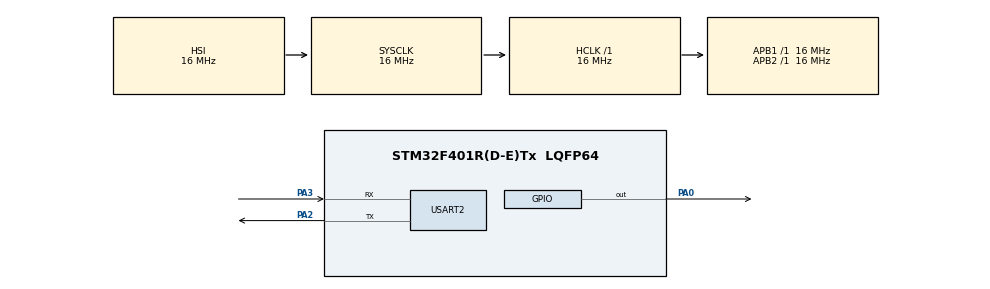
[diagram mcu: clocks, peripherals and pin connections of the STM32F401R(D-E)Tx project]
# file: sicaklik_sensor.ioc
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Mcu.Family=STM32F4
Mcu.Name=STM32F401R(D-E)Tx
Mcu.Package=LQFP64
NVIC.PriorityGroup=NVIC_PRIORITYGROUP_4
NVIC.USART2_IRQn=true\:0\:0\:false\:false\:true\:true\:true\:true
PA0-WKUP.GPIO_ModeDefaultOutputPP=GPIO_MODE_OUTPUT_OD
PA0-WKUP.GPIO_PuPd=GPIO_NOPULL
PA0-WKUP.PinState=GPIO_PIN_SET
PA0-WKUP.Signal=GPIO_Output
PA13.Mode=Serial_Wire
PA13.Signal=SYS_JTMS-SWDIO
PA14.Mode=Serial_Wire
PA14.Signal=SYS_JTCK-SWCLK
PA2.Mode=Asynchronous
PA2.Signal=USART2_TX
PA3.Mode=Asynchronous
PA3.Signal=USART2_RX
PH0\ -\ OSC_IN.Mode=HSE-External-Oscillator
PH0\ -\ OSC_IN.Signal=RCC_OSC_IN
PH1\ -\ OSC_OUT.Mode=HSE-External-Oscillator
PH1\ -\ OSC_OUT.Signal=RCC_OSC_OUT
ProjectManager.HeapSize=0x200
ProjectManager.StackSize=0x400
ProjectManager.TargetToolchain=STM32CubeIDE
RCC.AHBFreq_Value=16000000
RCC.APB1Freq_Value=16000000
RCC.APB2Freq_Value=16000000
RCC.CortexFreq_Value=16000000
RCC.HSE_VALUE=25000000
RCC.HSI_VALUE=16000000
RCC.LSE_VALUE=32768
RCC.SYSCLKFreq_VALUE=16000000
RCC.VCOOutputFreq_Value=192000000
TIM2.AutoReloadPreload=TIM_AUTORELOAD_PRELOAD_ENABLE
TIM2.Period=65535
TIM2.Prescaler=15
USART2.VirtualMode=VM_ASYNC
VP_TIM2_VS_ClockSourceINT.Mode=Internal
board=custom

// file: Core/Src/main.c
/* USER CODE BEGIN Header */
/**
  ******************************************************************************
  * @file           : main.c
  * @brief          : DS18B20 Telemetry System - 3 Sensors + Loop Hz + Uptime
  ******************************************************************************
  */
/* USER CODE END Header */
#include "main.h"
#include "stdio.h"

TIM_HandleTypeDef htim2;

UART_HandleTypeDef huart2;

/* USER CODE BEGIN PV */
// Sensör Kimlikleri (Sabit)
uint8_t S1_ID[8] = {0x28, 0x86, 0x84, 0x37, 0x00, 0x00, 0x00, 0x5C};
uint8_t S2_ID[8] = {0x28, 0xCC, 0x48, 0x38, 0x00, 0x00, 0x00, 0x7F};
uint8_t S3_ID[8] = {0x28, 0xE7, 0xB4, 0x36, 0x00, 0x00, 0x00, 0xA3};

// Sıcaklık ve Telemetri Değişkenleri
float T1 = 0, T2 = 0, T3 = 0;
float Loop_Hz = 0;
uint32_t last_tick = 0;
uint32_t current_uptime = 0;

char msg_buffer[150];
/* USER CODE END PV */

void SystemClock_Config(void);
static void MX_GPIO_Init(void);
static void MX_TIM2_Init(void);
static void MX_USART2_UART_Init(void);
/* USER CODE BEGIN PFP */
void delay_us (uint16_t us);
uint8_t DS18B20_Start (void);
void DS18B20_Write (uint8_t data);
uint8_t DS18B20_Read (void);
void DS18B20_Config9Bit(void);
float DS18B20_Read_By_ID(uint8_t *ID);
/* USER CODE END PFP */

/* USER CODE BEGIN 0 */
void delay_us (uint16_t us) {
    __HAL_TIM_SET_COUNTER(&htim2, 0);
    while (__HAL_TIM_GET_COUNTER(&htim2) < us);
}

void DS18B20_Config9Bit(void) {
    if (DS18B20_Start()) {
        DS18B20_Write(0xCC); // Skip ROM
        DS18B20_Write(0x4E); // Write Scratchpad
        DS18B20_Write(0x00); // TH
        DS18B20_Write(0x00); // TL
        DS18B20_Write(0x1F); // 9-bit resolution
    }
}

uint8_t DS18B20_Start (void) {
    uint8_t Response = 0;
    HAL_GPIO_WritePin(GPIOA, GPIO_PIN_0, 0);
    delay_us(480);
    HAL_GPIO_WritePin(GPIOA, GPIO_PIN_0, 1);
    delay_us(80);
    if (!(HAL_GPIO_ReadPin(GPIOA, GPIO_PIN_0))) Response = 1;
    else Response = 0;
    delay_us(400);
    return Response;
}

void DS18B20_Write (uint8_t data) {
    for (int i=0; i<8; i++) {
        if ((data & (1<<i)) != 0) {
            HAL_GPIO_WritePin(GPIOA, GPIO_PIN_0, 0);
            delay_us(1);
            HAL_GPIO_WritePin(GPIOA, GPIO_PIN_0, 1);
            delay_us(60);
        } else {
            HAL_GPIO_WritePin(GPIOA, GPIO_PIN_0, 0);
            delay_us(60);
            HAL_GPIO_WritePin(GPIOA, GPIO_PIN_0, 1);
        }
    }
}

uint8_t DS18B20_Read (void) {
    uint8_t value = 0;
    for (int i=0; i<8; i++) {
        HAL_GPIO_WritePin(GPIOA, GPIO_PIN_0, 0);
        delay_us(2);
        HAL_GPIO_WritePin(GPIOA, GPIO_PIN_0, 1);
        delay_us(10);
        if (HAL_GPIO_ReadPin(GPIOA, GPIO_PIN_0)) value |= (1<<i);
        delay_us(50);
    }
    return value;
}

float DS18B20_Read_By_ID(uint8_t *ID) {
    uint8_t b1, b2;
    if (DS18B20_Start()) {
        DS18B20_Write(0x55); // Match ROM
        for (int i=0; i<8; i++) DS18B20_Write(ID[i]);
        DS18B20_Write(0xBE); // Read Scratchpad
        b1 = DS18B20_Read();
        b2 = DS18B20_Read();
        return (float)((int16_t)(b2 << 8) | b1) / 16.0;
    }
    return -99.0;
}
/* USER CODE END 0 */

int main(void)
{

  /* MCU Configuration--------------------------------------------------------*/

  /* Reset of all peripherals, Initializes the Flash interface and the Systick. */
  HAL_Init();

  /* Configure the system clock */
  SystemClock_Config();

  /* Initialize all configured peripherals */
  MX_GPIO_Init();
  MX_TIM2_Init();
  MX_USART2_UART_Init();
  /* USER CODE BEGIN 2 */
  HAL_TIM_Base_Start(&htim2);
  DS18B20_Config9Bit(); // Sensörleri hızlandır

  HAL_UART_Transmit(&huart1, (uint8_t*)"Telemetri Basliyor...\r\n", 23, 100);
  last_tick = HAL_GetTick();
  /* USER CODE END 2 */

  /* Infinite loop */
  while (1)
  {
	  // --- 1. FREKANS (Hz) VE UPTIME HESAPLAMA ---
	        uint32_t current_time = HAL_GetTick();
	        uint32_t delta = current_time - last_tick;

	        if(delta > 0) {
	            Loop_Hz = 1000.0f / delta; // Döngü kaç Hz ile dönüyor?
	        }
	        last_tick = current_time;
	        current_uptime = current_time / 1000; // Saniye cinsinden çalışma süresi

	        // --- 2. SENSÖRLERE ÖLÇÜM EMRİ VER (SKIP ROM) ---
	        DS18B20_Start();
	        DS18B20_Write(0xCC); // Tüm sensörlere seslen
	        DS18B20_Write(0x44); // Sıcaklığı ölçmeye başlayın (Convert T)

	        // 9-bit modunda 100ms beklemek yeterlidir (Hızlı okuma için)
	        HAL_Delay(100);

	        // --- 3. VERİLERİ KİMLİKLERİNE (ID) GÖRE TEK TEK ÇEK ---
	        T1 = DS18B20_Read_By_ID(S1_ID);
	        T2 = DS18B20_Read_By_ID(S2_ID);
	        T3 = DS18B20_Read_By_ID(S3_ID);

	        // --- 4. RASPBERRY PI İÇİN PAKETLE VE GÖNDER (USART2!) ---
	        char msg[128];
	        // Format: S1:24.50|S2:25.10|S3:23.85|HZ:9.50|UP:123
	        int len = sprintf(msg, "S1:%.2f|S2:%.2f|S3:%.2f|HZ:%.2f|UP:%lu\n",
	                          T1, T2, T3, Loop_Hz, (unsigned long)current_uptime);

	        // USB üzerinden göndermek için huart2 kullanıyoruz
	        HAL_UART_Transmit(&huart2, (uint8_t*)msg, len, 100);

	        // --- 5. SİSTEMİ BİRAZ RAHATLAT (OPSİYONEL) ---
	        // Arayüzün saniyede 10 paket (10Hz) alması yeterlidir.
	        HAL_Delay(10);
  }
}

void SystemClock_Config(void)
{
  RCC_OscInitTypeDef RCC_OscInitStruct = {0};
  RCC_ClkInitTypeDef RCC_ClkInitStruct = {0};

  /** Configure the main internal regulator output voltage
  */
  __HAL_RCC_PWR_CLK_ENABLE();
  __HAL_PWR_VOLTAGESCALING_CONFIG(PWR_REGULATOR_VOLTAGE_SCALE2);

  /** Initializes the RCC Oscillators according to the specified parameters
  * in the RCC_OscInitTypeDef structure.
  */
  RCC_OscInitStruct.OscillatorType = RCC_OSCILLATORTYPE_HSI;
  RCC_OscInitStruct.HSIState = RCC_HSI_ON;
  RCC_OscInitStruct.HSICalibrationValue = RCC_HSICALIBRATION_DEFAULT;
  RCC_OscInitStruct.PLL.PLLState = RCC_PLL_NONE;
  if (HAL_RCC_OscConfig(&RCC_OscInitStruct) != HAL_OK)
  {
    Error_Handler();
  }

  /** Initializes the CPU, AHB and APB buses clocks
  */
  RCC_ClkInitStruct.ClockType = RCC_CLOCKTYPE_HCLK|RCC_CLOCKTYPE_SYSCLK
                              |RCC_CLOCKTYPE_PCLK1|RCC_CLOCKTYPE_PCLK2;
  RCC_ClkInitStruct.SYSCLKSource = RCC_SYSCLKSOURCE_HSI;
  RCC_ClkInitStruct.AHBCLKDivider = RCC_SYSCLK_DIV1;
  RCC_ClkInitStruct.APB1CLKDivider = RCC_HCLK_DIV1;
  RCC_ClkInitStruct.APB2CLKDivider = RCC_HCLK_DIV1;

  if (HAL_RCC_ClockConfig(&RCC_ClkInitStruct, FLASH_LATENCY_0) != HAL_OK)
  {
    Error_Handler();
  }
}

static void MX_TIM2_Init(void)
{

  TIM_ClockConfigTypeDef sClockSourceConfig = {0};
  TIM_MasterConfigTypeDef sMasterConfig = {0};

  htim2.Instance = TIM2;
  htim2.Init.Prescaler = 15;
  htim2.Init.CounterMode = TIM_COUNTERMODE_UP;
  htim2.Init.Period = 65535;
  htim2.Init.ClockDivision = TIM_CLOCKDIVISION_DIV1;
  htim2.Init.AutoReloadPreload = TIM_AUTORELOAD_PRELOAD_ENABLE;
  if (HAL_TIM_Base_Init(&htim2) != HAL_OK)
  {
    Error_Handler();
  }
  sClockSourceConfig.ClockSource = TIM_CLOCKSOURCE_INTERNAL;
  if (HAL_TIM_ConfigClockSource(&htim2, &sClockSourceConfig) != HAL_OK)
  {
    Error_Handler();
  }
  sMasterConfig.MasterOutputTrigger = TIM_TRGO_RESET;
  sMasterConfig.MasterSlaveMode = TIM_MASTERSLAVEMODE_DISABLE;
  if (HAL_TIMEx_MasterConfigSynchronization(&htim2, &sMasterConfig) != HAL_OK)
  {
    Error_Handler();
  }

}

static void MX_USART2_UART_Init(void)
{

  huart2.Instance = USART2;
  huart2.Init.BaudRate = 115200;
  huart2.Init.WordLength = UART_WORDLENGTH_8B;
  huart2.Init.StopBits = UART_STOPBITS_1;
  huart2.Init.Parity = UART_PARITY_NONE;
  huart2.Init.Mode = UART_MODE_TX_RX;
  huart2.Init.HwFlowCtl = UART_HWCONTROL_NONE;
  huart2.Init.OverSampling = UART_OVERSAMPLING_16;
  if (HAL_UART_Init(&huart2) != HAL_OK)
  {
    Error_Handler();
  }

}

static void MX_GPIO_Init(void)
{
  GPIO_InitTypeDef GPIO_InitStruct = {0};

  /* GPIO Ports Clock Enable */
  __HAL_RCC_GPIOH_CLK_ENABLE();
  __HAL_RCC_GPIOA_CLK_ENABLE();

  /*Configure GPIO pin Output Level */
  HAL_GPIO_WritePin(GPIOA, GPIO_PIN_0, GPIO_PIN_SET);

  /*Configure GPIO pin : PA0 */
  GPIO_InitStruct.Pin = GPIO_PIN_0;
  GPIO_InitStruct.Mode = GPIO_MODE_OUTPUT_OD;
  GPIO_InitStruct.Pull = GPIO_NOPULL;
  GPIO_InitStruct.Speed = GPIO_SPEED_FREQ_LOW;
  HAL_GPIO_Init(GPIOA, &GPIO_InitStruct);

}

void Error_Handler(void)
{
  __disable_irq();
  while (1)
  {
  }
}
